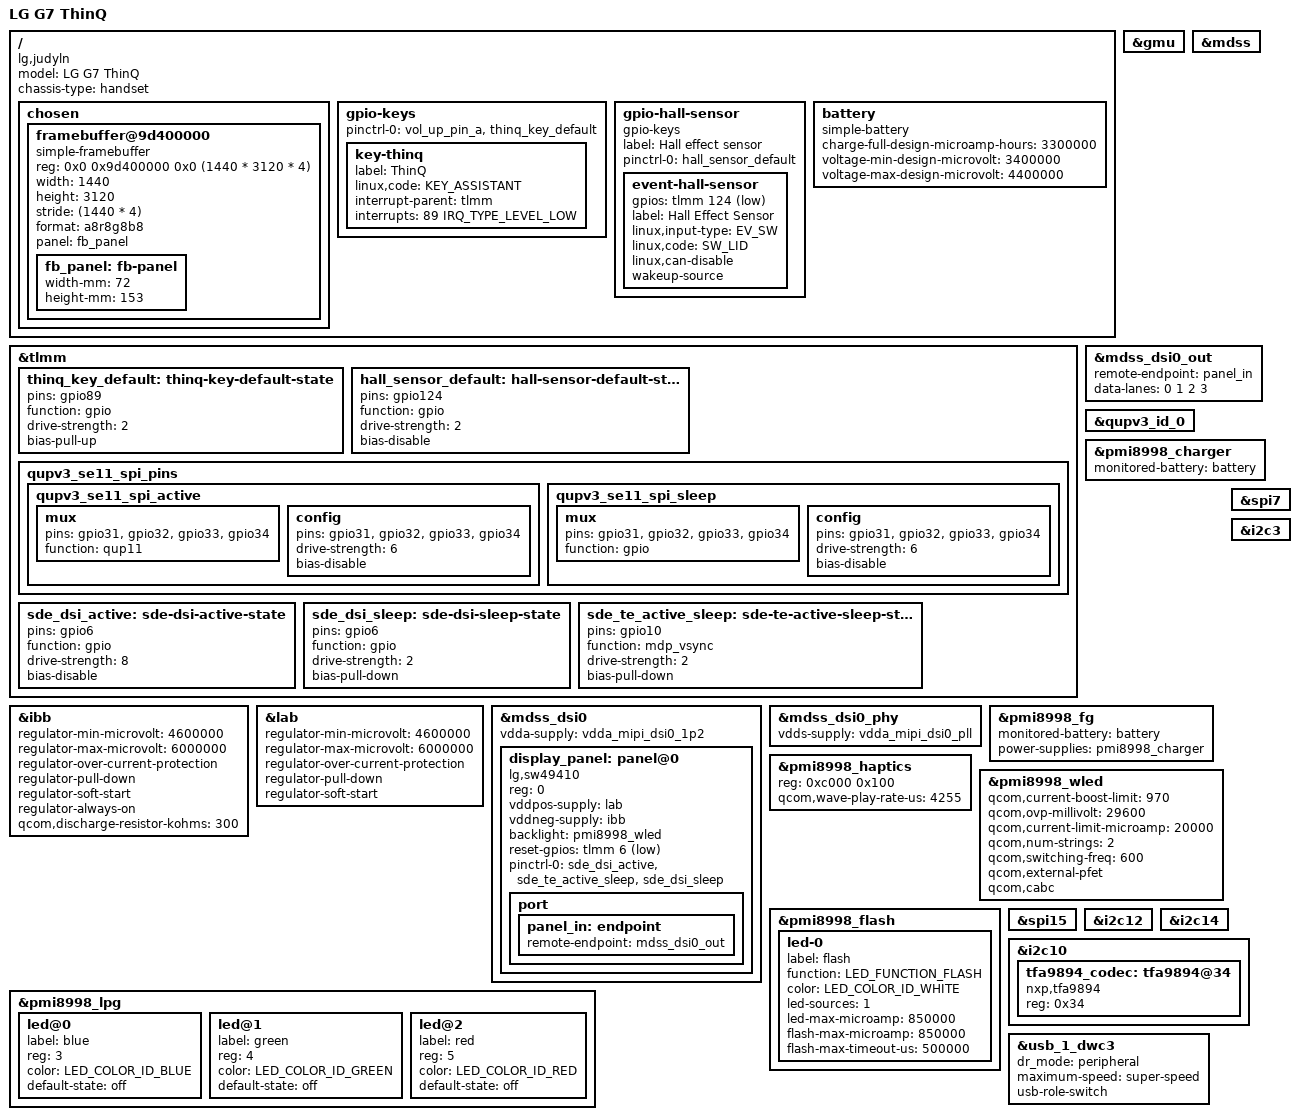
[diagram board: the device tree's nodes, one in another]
// SPDX-License-Identifier: GPL-2.0
/*
 * SDM845 LG G7 (judyln) device tree.
 *
 * Copyright (c) 2022, The Linux Foundation. All rights reserved.
 */

/dts-v1/;

#include "sdm845-lg-common.dtsi"
#include <dt-bindings/leds/common.h>

/ {
	model = "LG G7 ThinQ";
	compatible = "lg,judyln", "qcom,sdm845";
	chassis-type = "handset";

	chosen {
		framebuffer@9d400000 {
			compatible = "simple-framebuffer";
			reg = <0x0 0x9d400000 0x0 (1440 * 3120 * 4)>;
			width = <1440>;
			height = <3120>;
			stride = <(1440 * 4)>;
			format = "a8r8g8b8";

			panel = <&fb_panel>;

			fb_panel: fb-panel {
				width-mm = <72>;
				height-mm = <153>;
			};
		};
	};

	/* Additional ThinQ key */
	gpio-keys {
		pinctrl-0 = <&vol_up_pin_a &thinq_key_default>;

		key-thinq {
			label = "ThinQ";
			linux,code = <KEY_ASSISTANT>;
			interrupt-parent = <&tlmm>;
			interrupts = <89 IRQ_TYPE_LEVEL_LOW>;
		};
	};

	gpio-hall-sensor {
		compatible = "gpio-keys";
		label = "Hall effect sensor";

		pinctrl-0 = <&hall_sensor_default>;
		pinctrl-names = "default";

		event-hall-sensor {
			gpios = <&tlmm 124 GPIO_ACTIVE_LOW>;
			label = "Hall Effect Sensor";
			linux,input-type = <EV_SW>;
			linux,code = <SW_LID>;
			linux,can-disable;
			wakeup-source;
		};
	};

	battery: battery {
		status = "okay";
		compatible = "simple-battery";

		charge-full-design-microamp-hours = <3300000>;
		voltage-min-design-microvolt = <3400000>;
		voltage-max-design-microvolt = <4400000>;
	};
};

&gmu {
	status = "okay";
};

&tlmm {
	thinq_key_default: thinq-key-default-state {
		pins = "gpio89";
		function = "gpio";

		drive-strength = <2>;
		bias-pull-up;
	};

	hall_sensor_default: hall-sensor-default-state {
		pins = "gpio124";
		function = "gpio";

		drive-strength = <2>;
		bias-disable;
	};

	qupv3_se11_spi_pins: qupv3_se11_spi_pins {
		qupv3_se11_spi_active: qupv3_se11_spi_active {
			mux {
				pins = "gpio31", "gpio32", "gpio33",
							"gpio34";
				function = "qup11";
			};

			config {
				pins = "gpio31", "gpio32", "gpio33",
							"gpio34";
				drive-strength = <6>;
				bias-disable;
			};
		};

		qupv3_se11_spi_sleep: qupv3_se11_spi_sleep {
			mux {
				pins = "gpio31", "gpio32", "gpio33",
							"gpio34";
				function = "gpio";
			};

			config {
				pins = "gpio31", "gpio32", "gpio33",
							"gpio34";
				drive-strength = <6>;
				bias-disable;
			};
		};
	};

	sde_dsi_active: sde-dsi-active-state {
		pins = "gpio6";
		function = "gpio";
		drive-strength = <8>;
		bias-disable;
	};

	sde_dsi_sleep: sde-dsi-sleep-state {
		pins = "gpio6";
		function = "gpio";
		drive-strength = <2>;
		bias-pull-down;
	};

	sde_te_active_sleep: sde-te-active-sleep-state {
		pins = "gpio10";
		function = "mdp_vsync";
		drive-strength = <2>;
		bias-pull-down;
	};
};

&mdss {
	status = "okay";
};

&ibb {
	regulator-min-microvolt = <4600000>;
	regulator-max-microvolt = <6000000>;
	regulator-over-current-protection;
	regulator-pull-down;
	regulator-soft-start;
	regulator-always-on;
	qcom,discharge-resistor-kohms = <300>;
};

&lab {
	regulator-min-microvolt = <4600000>;
	regulator-max-microvolt = <6000000>;
	regulator-over-current-protection;
	regulator-pull-down;
	regulator-soft-start;
};

&mdss_dsi0 {
	status = "okay";
	vdda-supply = <&vdda_mipi_dsi0_1p2>;

	display_panel: panel@0 {
		reg = <0>;
		compatible = "lg,sw49410";

		vddpos-supply = <&lab>;
		vddneg-supply = <&ibb>;

		backlight = <&pmi8998_wled>;
		reset-gpios = <&tlmm 6 GPIO_ACTIVE_LOW>;

		pinctrl-names = "default";
		pinctrl-0 = <&sde_dsi_active &sde_te_active_sleep &sde_dsi_sleep>;

		port {
			panel_in: endpoint {
				remote-endpoint = <&mdss_dsi0_out>;
			};
		};
	};
};

&mdss_dsi0_phy {
	status = "okay";
	vdds-supply = <&vdda_mipi_dsi0_pll>;
};

&mdss_dsi0_out {
	remote-endpoint = <&panel_in>;
	data-lanes = <0 1 2 3>;
};

&qupv3_id_0 {
	status = "okay";
};

&pmi8998_charger {
	status = "okay";
	monitored-battery = <&battery>;
};

&pmi8998_fg {
	status = "okay";
	monitored-battery = <&battery>;
	power-supplies = <&pmi8998_charger>;
};

&pmi8998_haptics {
	status = "okay";
	reg = <0xc000 0x100>;

	qcom,wave-play-rate-us = <4255>;
};

&pmi8998_lpg {
	status = "okay";

	led@0 {
		label = "blue";
		reg = <3>;
		color = <LED_COLOR_ID_BLUE>;
		default-state = "off";
	};

	led@1 {
		label = "green";
		reg = <4>;
		color = <LED_COLOR_ID_GREEN>;
		default-state = "off";
	};

	led@2 {
		label = "red";
		reg = <5>;
		color = <LED_COLOR_ID_RED>;
		default-state = "off";
	};
};

&pmi8998_wled {
	status = "okay";
	qcom,current-boost-limit = <970>;
	qcom,ovp-millivolt = <29600>;
	qcom,current-limit-microamp = <20000>;
	qcom,num-strings = <2>;
	qcom,switching-freq = <600>;
	qcom,external-pfet;
	qcom,cabc;
};

&pmi8998_flash {
	status = "okay";

	led-0 {
		label = "flash";
		function = LED_FUNCTION_FLASH;
		color = <LED_COLOR_ID_WHITE>;
		led-sources = <1>;
		led-max-microamp = <850000>;
		flash-max-microamp = <850000>;
		flash-max-timeout-us = <500000>;
	};

};

&spi7 {
	status = "okay";
};

&spi15 {
	status = "okay";
};

&i2c3 {
	status = "okay";
};

&i2c12 {
	status = "okay";
};

&i2c14 {
	status = "okay";
};

&i2c10 {
	status = "okay";

	tfa9894_codec: tfa9894@34 {
		#sound-dai-cells = <1>;
		compatible = "nxp,tfa9894";
		reg = <0x34>;
	};
};

&usb_1_dwc3 {
	dr_mode = "peripheral";
	maximum-speed = "super-speed";
	usb-role-switch;
};
